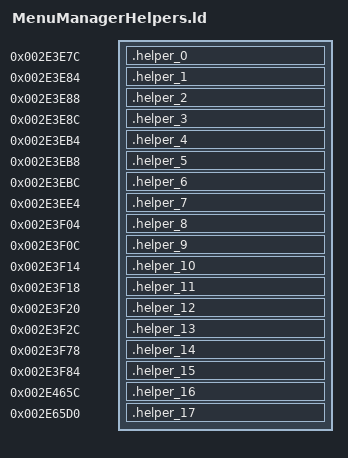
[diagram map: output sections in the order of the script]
OUTPUT_FORMAT("elf32-littlearm")
OUTPUT_ARCH(arm)
SECTIONS
{
    .helper_0 0x002e3e7c : { *menu-manager-helpers.o(.text._ZN11MenuManager21resetWidgetVisibilityEv .gnu.linkonce.t._ZN11MenuManager21resetWidgetVisibilityEv) }
    .helper_1 0x002e3e84 : { *menu-manager-helpers.o(.text._ZN11MenuManager9MenuPauseEv .gnu.linkonce.t._ZN11MenuManager9MenuPauseEv) }
    .helper_2 0x002e3e88 : { *menu-manager-helpers.o(.text._ZN11MenuManager10MenuResumeEv .gnu.linkonce.t._ZN11MenuManager10MenuResumeEv) }
    .helper_3 0x002e3e8c : { *menu-manager-helpers.o(.text._ZN11MenuManager14setTutorialIdsEii .gnu.linkonce.t._ZN11MenuManager14setTutorialIdsEii) }
    .helper_4 0x002e3eb4 : { *menu-manager-helpers.o(.text._ZN11MenuManager13setRepairCostEi .gnu.linkonce.t._ZN11MenuManager13setRepairCostEi) }
    .helper_5 0x002e3eb8 : { *menu-manager-helpers.o(.text._ZNK11MenuManager13getRepairCostEv .gnu.linkonce.t._ZNK11MenuManager13getRepairCostEv) }
    .helper_6 0x002e3ebc : { *menu-manager-helpers.o(.text._ZNK11MenuManager17areCheatsUnlockedEv .gnu.linkonce.t._ZNK11MenuManager17areCheatsUnlockedEv) }
    .helper_7 0x002e3ee4 : { *menu-manager-helpers.o(.text._ZNK11MenuManager21isCheatsUnlockAllowedEv .gnu.linkonce.t._ZNK11MenuManager21isCheatsUnlockAllowedEv) }
    .helper_8 0x002e3f04 : { *menu-manager-helpers.o(.text._ZNK11MenuManager15isClearingFocusEv .gnu.linkonce.t._ZNK11MenuManager15isClearingFocusEv) }
    .helper_9 0x002e3f0c : { *menu-manager-helpers.o(.text._ZN11MenuManager9getMenuFXEv .gnu.linkonce.t._ZN11MenuManager9getMenuFXEv) }
    .helper_10 0x002e3f14 : { *menu-manager-helpers.o(.text._ZNK11MenuManager12isInGameMenuEv .gnu.linkonce.t._ZNK11MenuManager12isInGameMenuEv) }
    .helper_11 0x002e3f18 : { *menu-manager-helpers.o(.text._ZNK11MenuManager15consumedCursorsEv .gnu.linkonce.t._ZNK11MenuManager15consumedCursorsEv) }
    .helper_12 0x002e3f20 : { *menu-manager-helpers.o(.text._ZN11MenuManager13consumeCursorEv .gnu.linkonce.t._ZN11MenuManager13consumeCursorEv) }
    .helper_13 0x002e3f2c : { *menu-manager-helpers.o(.text._ZN11MenuManager19getCharAutoLineFeedEv .gnu.linkonce.t._ZN11MenuManager19getCharAutoLineFeedEv) }
    .helper_14 0x002e3f78 : { *menu-manager-helpers.o(.text._ZN11MenuManager11enableAnimsEb .gnu.linkonce.t._ZN11MenuManager11enableAnimsEb) }
    .helper_15 0x002e3f84 : { *menu-manager-helpers.o(.text._ZNK11MenuManager15areAnimsEnabledEv .gnu.linkonce.t._ZNK11MenuManager15areAnimsEnabledEv) }
    .helper_16 0x002e465c : { *menu-manager-helpers.o(.text._ZNK11MenuManager8getDepthEv .gnu.linkonce.t._ZNK11MenuManager8getDepthEv) }
    .helper_17 0x002e65d0 : { *menu-manager-helpers.o(.text._ZNK11MenuManager10getMapModeEv .gnu.linkonce.t._ZNK11MenuManager10getMapModeEv) }
}
